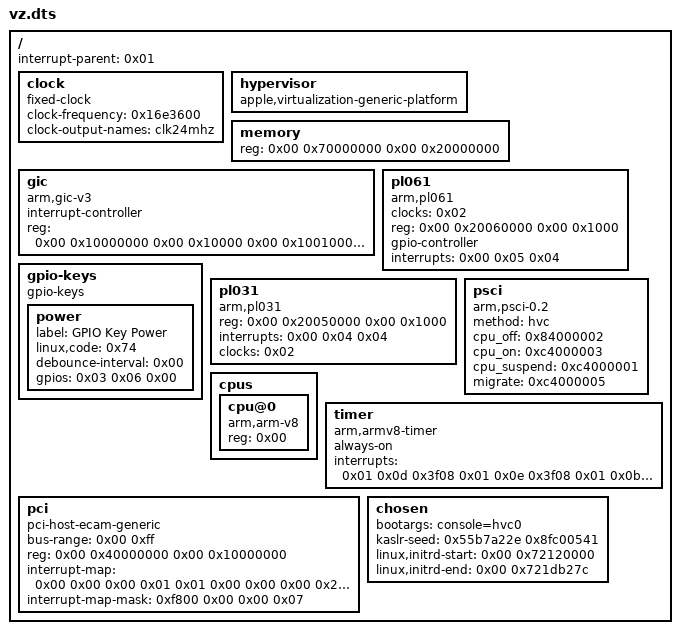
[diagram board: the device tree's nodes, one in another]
/dts-v1/;

/ {
	#address-cells = <0x02>;
	#size-cells = <0x02>;
	interrupt-parent = <0x01>;

	clock {
		#clock-cells = <0x00>;
		clock-frequency = <0x16e3600>;
		phandle = <0x02>;
		clock-output-names = "clk24mhz";
		compatible = "fixed-clock";
	};

	hypervisor {
		compatible = "apple,virtualization-generic-platform";
	};

	memory {
		device_type = "memory";
		reg = <0x00 0x70000000 0x00 0x20000000>;
	};

	gic {
		phandle = <0x01>;
		compatible = "arm,gic-v3";
		#address-cells = <0x02>;
		#size-cells = <0x02>;
		#interrupt-cells = <0x03>;
		interrupt-controller;
		ranges;
		reg = <0x00 0x10000000 0x00 0x10000 0x00 0x10010000 0x00 0x20000>;
	};

	pl061 {
		compatible = "arm,pl061", "arm,primecell";
		clocks = <0x02>;
		clock-names = "apb_pclk";
		phandle = <0x03>;
		reg = <0x00 0x20060000 0x00 0x1000>;
		gpio-controller;
		#gpio-cells = <0x02>;
		interrupts = <0x00 0x05 0x04>;
	};

	gpio-keys {
		compatible = "gpio-keys";

		power {
			label = "GPIO Key Power";
			linux,code = <0x74>;
			debounce-interval = <0x00>;
			gpios = <0x03 0x06 0x00>;
		};
	};

	pl031 {
		compatible = "arm,pl031", "arm,primecell";
		reg = <0x00 0x20050000 0x00 0x1000>;
		interrupts = <0x00 0x04 0x04>;
		clocks = <0x02>;
		clock-names = "apb_pclk";
	};

	psci {
		compatible = "arm,psci-0.2";
		method = "hvc";
		cpu_off = <0x84000002>;
		cpu_on = <0xc4000003>;
		cpu_suspend = <0xc4000001>;
		migrate = <0xc4000005>;
	};

	cpus {
		#address-cells = <0x01>;
		#size-cells = <0x00>;

		cpu@0 {
			device_type = "cpu";
			compatible = "arm,arm-v8";
			reg = <0x00>;
		};
	};

	timer {
		compatible = "arm,armv8-timer";
		always-on;
		interrupts = <0x01 0x0d 0x3f08 0x01 0x0e 0x3f08 0x01 0x0b 0x3f08 0x01 0x0a 0x3f08>;
	};

	pci {
		compatible = "pci-host-ecam-generic";
		device_type = "pci";
		#address-cells = <0x03>;
		#size-cells = <0x02>;
		#interrupt-cells = <0x01>;
		bus-range = <0x00 0xff>;
		reg = <0x00 0x40000000 0x00 0x10000000>;
		ranges = <0x1000000 0x00 0x00 0x00 0x6fff0000 0x00 0x10000 0x2000000 0x00 0x50000000 0x00 0x50000000 0x00 0x1ffe0000 0x3000000 0x01 0x00 0x01 0x00 0x04 0x00>;
		interrupt-map = <0x00 0x00 0x00 0x01 0x01 0x00 0x00 0x00 0x20 0x04 0x800 0x00 0x00 0x01 0x01 0x00 0x00 0x00 0x21 0x04 0x1000 0x00 0x00 0x01 0x01 0x00 0x00 0x00 0x22 0x04 0x1800 0x00 0x00 0x01 0x01 0x00 0x00 0x00 0x23 0x04 0x2000 0x00 0x00 0x01 0x01 0x00 0x00 0x00 0x24 0x04 0x2800 0x00 0x00 0x01 0x01 0x00 0x00 0x00 0x25 0x04 0x3000 0x00 0x00 0x01 0x01 0x00 0x00 0x00 0x26 0x04 0x3800 0x00 0x00 0x01 0x01 0x00 0x00 0x00 0x27 0x04 0x4000 0x00 0x00 0x01 0x01 0x00 0x00 0x00 0x28 0x04 0x4800 0x00 0x00 0x01 0x01 0x00 0x00 0x00 0x29 0x04 0x5000 0x00 0x00 0x01 0x01 0x00 0x00 0x00 0x2a 0x04 0x5800 0x00 0x00 0x01 0x01 0x00 0x00 0x00 0x2b 0x04 0x6000 0x00 0x00 0x01 0x01 0x00 0x00 0x00 0x2c 0x04 0x6800 0x00 0x00 0x01 0x01 0x00 0x00 0x00 0x2d 0x04 0x7000 0x00 0x00 0x01 0x01 0x00 0x00 0x00 0x2e 0x04 0x7800 0x00 0x00 0x01 0x01 0x00 0x00 0x00 0x2f 0x04 0x8000 0x00 0x00 0x01 0x01 0x00 0x00 0x00 0x30 0x04 0x8800 0x00 0x00 0x01 0x01 0x00 0x00 0x00 0x31 0x04 0x9000 0x00 0x00 0x01 0x01 0x00 0x00 0x00 0x32 0x04 0x9800 0x00 0x00 0x01 0x01 0x00 0x00 0x00 0x33 0x04 0xa000 0x00 0x00 0x01 0x01 0x00 0x00 0x00 0x34 0x04 0xa800 0x00 0x00 0x01 0x01 0x00 0x00 0x00 0x35 0x04 0xb000 0x00 0x00 0x01 0x01 0x00 0x00 0x00 0x36 0x04 0xb800 0x00 0x00 0x01 0x01 0x00 0x00 0x00 0x37 0x04 0xc000 0x00 0x00 0x01 0x01 0x00 0x00 0x00 0x38 0x04 0xc800 0x00 0x00 0x01 0x01 0x00 0x00 0x00 0x39 0x04 0xd000 0x00 0x00 0x01 0x01 0x00 0x00 0x00 0x3a 0x04 0xd800 0x00 0x00 0x01 0x01 0x00 0x00 0x00 0x3b 0x04 0xe000 0x00 0x00 0x01 0x01 0x00 0x00 0x00 0x3c 0x04 0xe800 0x00 0x00 0x01 0x01 0x00 0x00 0x00 0x3d 0x04 0xf000 0x00 0x00 0x01 0x01 0x00 0x00 0x00 0x3e 0x04 0xf800 0x00 0x00 0x01 0x01 0x00 0x00 0x00 0x3f 0x04>;
		interrupt-map-mask = <0xf800 0x00 0x00 0x07>;
	};

	chosen {
		bootargs = "console=hvc0";
		kaslr-seed = <0x55b7a22e 0x8fc00541>;
		linux,initrd-start = <0x00 0x72120000>;
		linux,initrd-end = <0x00 0x721db27c>;
	};
};
